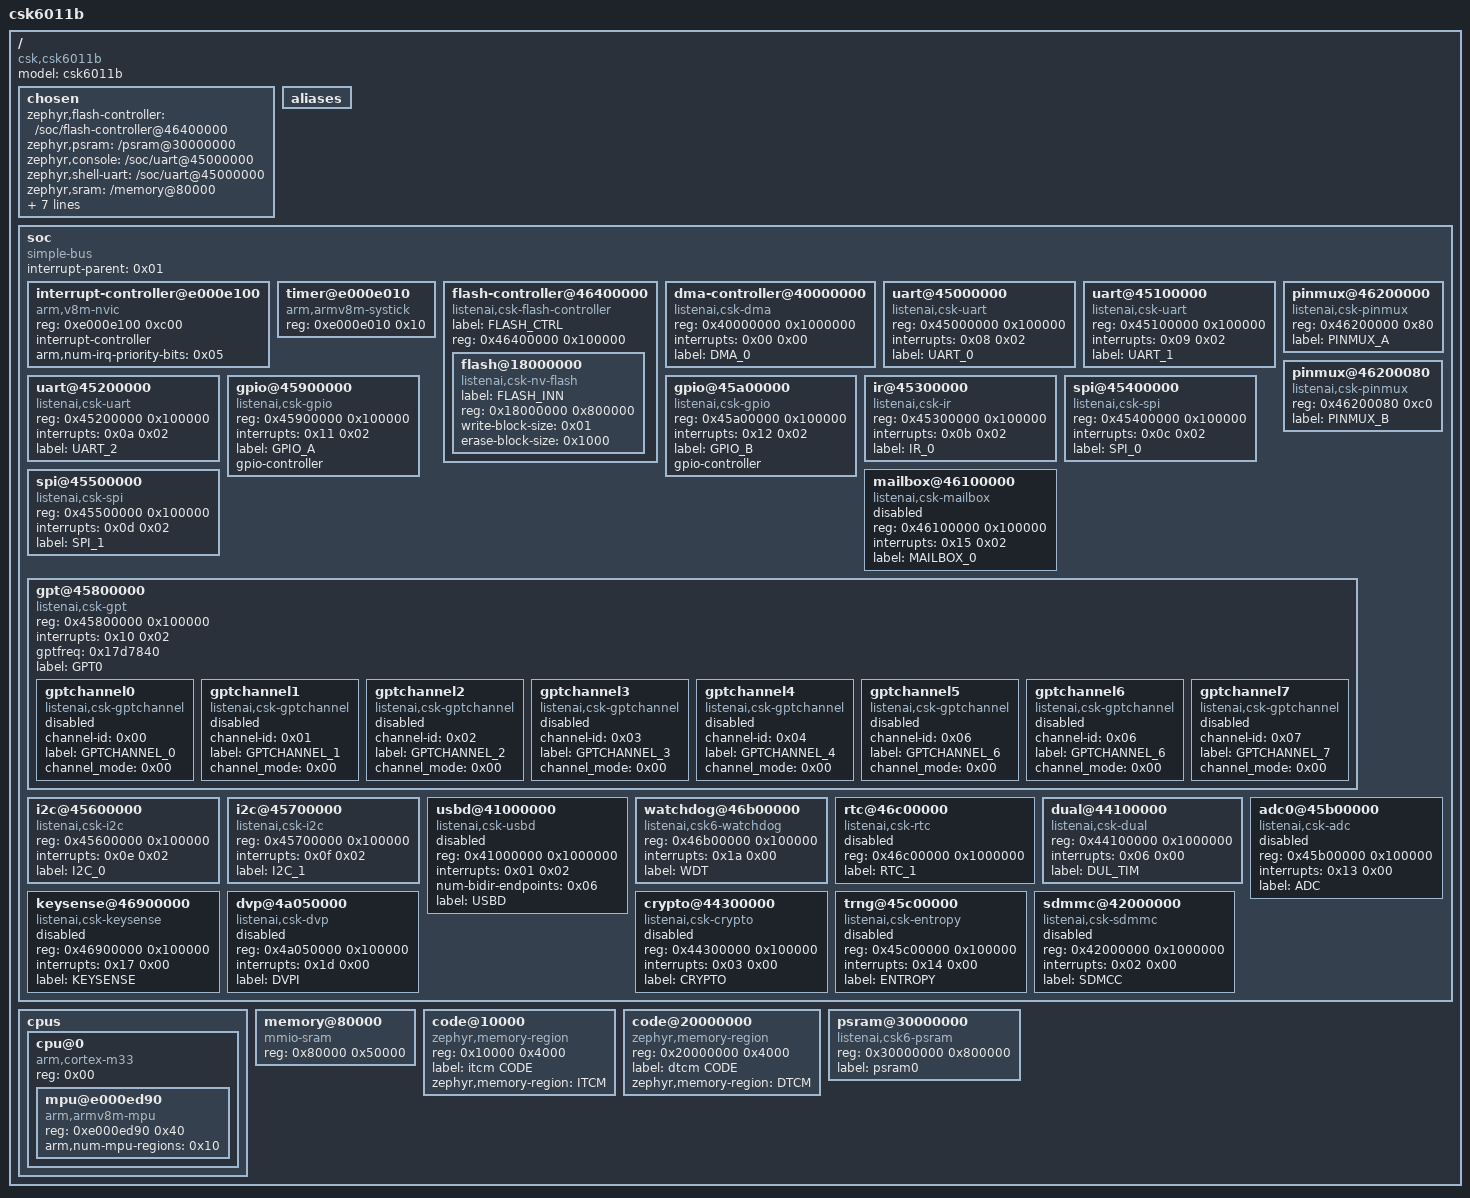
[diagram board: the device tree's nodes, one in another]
/dts-v1/;

/ {
	#address-cells = <0x01>;
	#size-cells = <0x01>;
	model = "csk6011b";
	compatible = "csk,csk6011b";

	chosen {
		zephyr,flash-controller = "/soc/flash-controller@46400000";
		zephyr,psram = "/psram@30000000";
		zephyr,console = "/soc/uart@45000000";
		zephyr,shell-uart = "/soc/uart@45000000";
		zephyr,sram = "/memory@80000";
		zephyr,itcm = "/code@10000";
		zephyr,dtcm = "/code@20000000";
		zephyr,flash = "/soc/flash-controller@46400000/flash@18000000";
		zephyr,flash_controller = "/soc/flash-controller@46400000";
		zephyr,entropy = "/soc/trng@45c00000";
	};

	aliases {
	};

	soc {
		#address-cells = <0x01>;
		#size-cells = <0x01>;
		compatible = "simple-bus";
		interrupt-parent = <0x01>;
		ranges;

		interrupt-controller@e000e100 {
			#address-cells = <0x01>;
			compatible = "arm,v8m-nvic";
			reg = <0xe000e100 0xc00>;
			interrupt-controller;
			#interrupt-cells = <0x02>;
			arm,num-irq-priority-bits = <0x05>;
			phandle = <0x01>;
		};

		timer@e000e010 {
			compatible = "arm,armv8m-systick";
			reg = <0xe000e010 0x10>;
		};

		flash-controller@46400000 {
			compatible = "listenai,csk-flash-controller";
			label = "FLASH_CTRL";
			reg = <0x46400000 0x100000>;
			#address-cells = <0x01>;
			#size-cells = <0x01>;

			flash@18000000 {
				compatible = "listenai,csk-nv-flash", "soc-nv-flash";
				label = "FLASH_INN";
				reg = <0x18000000 0x800000>;
				write-block-size = <0x01>;
				erase-block-size = <0x1000>;
			};
		};

		dma-controller@40000000 {
			compatible = "listenai,csk-dma";
			reg = <0x40000000 0x1000000>;
			interrupts = <0x00 0x00>;
			label = "DMA_0";
			#dma-cells = <0x01>;
		};

		uart@45000000 {
			compatible = "listenai,csk-uart";
			reg = <0x45000000 0x100000>;
			interrupts = <0x08 0x02>;
			label = "UART_0";
		};

		uart@45100000 {
			compatible = "listenai,csk-uart";
			reg = <0x45100000 0x100000>;
			interrupts = <0x09 0x02>;
			label = "UART_1";
		};

		uart@45200000 {
			compatible = "listenai,csk-uart";
			reg = <0x45200000 0x100000>;
			interrupts = <0x0a 0x02>;
			label = "UART_2";
		};

		pinmux@46200000 {
			compatible = "listenai,csk-pinmux";
			reg = <0x46200000 0x80>;
			#pinmux-cells = <0x02>;
			#pinctrl-cells = <0x02>;
			label = "PINMUX_A";
			status = "okay";
		};

		pinmux@46200080 {
			compatible = "listenai,csk-pinmux";
			reg = <0x46200080 0xc0>;
			#pinmux-cells = <0x02>;
			#pinctrl-cells = <0x02>;
			label = "PINMUX_B";
			status = "okay";
		};

		gpio@45900000 {
			compatible = "listenai,csk-gpio";
			reg = <0x45900000 0x100000>;
			interrupts = <0x11 0x02>;
			label = "GPIO_A";
			gpio-controller;
			#gpio-cells = <0x02>;
		};

		gpio@45a00000 {
			compatible = "listenai,csk-gpio";
			reg = <0x45a00000 0x100000>;
			interrupts = <0x12 0x02>;
			label = "GPIO_B";
			gpio-controller;
			#gpio-cells = <0x02>;
		};

		ir@45300000 {
			compatible = "listenai,csk-ir";
			reg = <0x45300000 0x100000>;
			interrupts = <0x0b 0x02>;
			label = "IR_0";
		};

		spi@45400000 {
			compatible = "listenai,csk-spi";
			reg = <0x45400000 0x100000>;
			interrupts = <0x0c 0x02>;
			label = "SPI_0";
			#address-cells = <0x01>;
			#size-cells = <0x00>;
		};

		spi@45500000 {
			compatible = "listenai,csk-spi";
			reg = <0x45500000 0x100000>;
			interrupts = <0x0d 0x02>;
			label = "SPI_1";
			#address-cells = <0x01>;
			#size-cells = <0x00>;
		};

		mailbox@46100000 {
			compatible = "listenai,csk-mailbox";
			reg = <0x46100000 0x100000>;
			interrupts = <0x15 0x02>;
			label = "MAILBOX_0";
			status = "disabled";
		};

		gpt@45800000 {
			compatible = "listenai,csk-gpt";
			reg = <0x45800000 0x100000>;
			interrupts = <0x10 0x02>;
			interrupt-names = "csk_gpt_isr";
			gptfreq = <0x17d7840>;
			label = "GPT0";

			gptchannel0 {
				compatible = "listenai,csk-gptchannel";
				channel-id = <0x00>;
				label = "GPTCHANNEL_0";
				channel_mode = <0x00>;
				status = "disabled";
				#pwm-cells = <0x03>;
			};

			gptchannel1 {
				compatible = "listenai,csk-gptchannel";
				channel-id = <0x01>;
				label = "GPTCHANNEL_1";
				channel_mode = <0x00>;
				status = "disabled";
				#pwm-cells = <0x03>;
			};

			gptchannel2 {
				compatible = "listenai,csk-gptchannel";
				channel-id = <0x02>;
				label = "GPTCHANNEL_2";
				channel_mode = <0x00>;
				status = "disabled";
				#pwm-cells = <0x03>;
			};

			gptchannel3 {
				compatible = "listenai,csk-gptchannel";
				channel-id = <0x03>;
				label = "GPTCHANNEL_3";
				channel_mode = <0x00>;
				status = "disabled";
				#pwm-cells = <0x03>;
			};

			gptchannel4 {
				compatible = "listenai,csk-gptchannel";
				channel-id = <0x04>;
				label = "GPTCHANNEL_4";
				channel_mode = <0x00>;
				status = "disabled";
				#pwm-cells = <0x03>;
			};

			gptchannel5 {
				compatible = "listenai,csk-gptchannel";
				channel-id = <0x06>;
				label = "GPTCHANNEL_6";
				channel_mode = <0x00>;
				status = "disabled";
				#pwm-cells = <0x03>;
			};

			gptchannel6 {
				compatible = "listenai,csk-gptchannel";
				channel-id = <0x06>;
				label = "GPTCHANNEL_6";
				channel_mode = <0x00>;
				status = "disabled";
				#pwm-cells = <0x03>;
			};

			gptchannel7 {
				compatible = "listenai,csk-gptchannel";
				channel-id = <0x07>;
				label = "GPTCHANNEL_7";
				channel_mode = <0x00>;
				status = "disabled";
				#pwm-cells = <0x03>;
			};
		};

		i2c@45600000 {
			compatible = "listenai,csk-i2c";
			reg = <0x45600000 0x100000>;
			interrupts = <0x0e 0x02>;
			#address-cells = <0x01>;
			#size-cells = <0x00>;
			label = "I2C_0";
		};

		i2c@45700000 {
			compatible = "listenai,csk-i2c";
			reg = <0x45700000 0x100000>;
			interrupts = <0x0f 0x02>;
			#address-cells = <0x01>;
			#size-cells = <0x00>;
			label = "I2C_1";
		};

		usbd@41000000 {
			compatible = "listenai,csk-usbd";
			reg = <0x41000000 0x1000000>;
			interrupts = <0x01 0x02>;
			interrupt-names = "usb_otg";
			num-bidir-endpoints = <0x06>;
			status = "disabled";
			label = "USBD";
		};

		watchdog@46b00000 {
			compatible = "listenai,csk6-watchdog";
			reg = <0x46b00000 0x100000>;
			interrupts = <0x1a 0x00>;
			label = "WDT";
			status = "okay";
		};

		rtc@46c00000 {
			compatible = "listenai,csk-rtc";
			reg = <0x46c00000 0x1000000>;
			status = "disabled";
			label = "RTC_1";
		};

		dual@44100000 {
			compatible = "listenai,csk-dual";
			reg = <0x44100000 0x1000000>;
			interrupts = <0x06 0x00>;
			label = "DUL_TIM";
		};

		adc0@45b00000 {
			compatible = "listenai,csk-adc";
			reg = <0x45b00000 0x100000>;
			interrupts = <0x13 0x00>;
			status = "disabled";
			label = "ADC";
			#io-channel-cells = <0x01>;
		};

		keysense@46900000 {
			compatible = "listenai,csk-keysense";
			reg = <0x46900000 0x100000>;
			interrupts = <0x17 0x00>;
			status = "disabled";
			label = "KEYSENSE";
		};

		dvp@4a050000 {
			compatible = "listenai,csk-dvp";
			reg = <0x4a050000 0x100000>;
			interrupts = <0x1d 0x00>;
			status = "disabled";
			label = "DVPI";
		};

		crypto@44300000 {
			compatible = "listenai,csk-crypto";
			reg = <0x44300000 0x100000>;
			interrupts = <0x03 0x00>;
			status = "disabled";
			label = "CRYPTO";
		};

		trng@45c00000 {
			compatible = "listenai,csk-entropy";
			reg = <0x45c00000 0x100000>;
			interrupts = <0x14 0x00>;
			status = "disabled";
			label = "ENTROPY";
		};

		sdmmc@42000000 {
			compatible = "listenai,csk-sdmmc";
			reg = <0x42000000 0x1000000>;
			interrupts = <0x02 0x00>;
			status = "disabled";
			label = "SDMCC";
		};
	};

	cpus {
		#address-cells = <0x01>;
		#size-cells = <0x00>;

		cpu@0 {
			device_type = "cpu";
			compatible = "arm,cortex-m33";
			reg = <0x00>;
			#address-cells = <0x01>;
			#size-cells = <0x01>;

			mpu@e000ed90 {
				compatible = "arm,armv8m-mpu";
				reg = <0xe000ed90 0x40>;
				arm,num-mpu-regions = <0x10>;
			};
		};
	};

	memory@80000 {
		compatible = "mmio-sram";
		reg = <0x80000 0x50000>;
	};

	code@10000 {
		compatible = "zephyr,memory-region";
		reg = <0x10000 0x4000>;
		label = "itcm CODE";
		zephyr,memory-region = "ITCM";
	};

	code@20000000 {
		compatible = "zephyr,memory-region";
		reg = <0x20000000 0x4000>;
		label = "dtcm CODE";
		zephyr,memory-region = "DTCM";
	};

	psram@30000000 {
		compatible = "listenai,csk6-psram";
		reg = <0x30000000 0x800000>;
		label = "psram0";
	};
};
